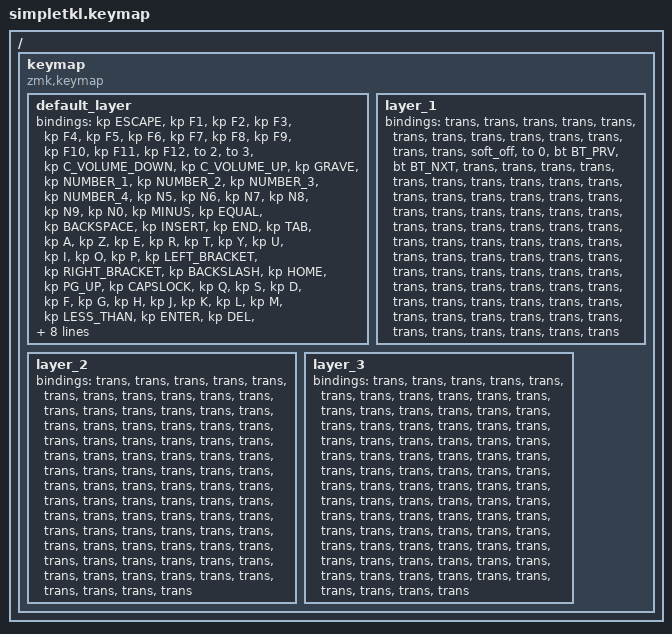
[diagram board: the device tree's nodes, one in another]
/*
 * Keymap for: simpletkl
 *
 * This keymap MUST match your PHYSICAL layout (17 rows, 6 columns).
 * Use &none for any empty spots in the matrix.
 */

#include <dt-bindings/zmk/matrix_transform.h> // Required for matrix_transform
#include <behaviors.dtsi>
#include <dt-bindings/zmk/bt.h>
#include <dt-bindings/zmk/keys.h>

/ {
    keymap {
        compatible = "zmk,keymap";

        default_layer {
            bindings = <
&kp ESCAPE  &kp F1  &kp F2  &kp F3  &kp F4  &kp F5  &kp F6  &kp F7  &kp F8  &kp F9  &kp F10  &kp F11  &kp F12  &to 2  &to 3  &kp C_VOLUME_DOWN  &kp C_VOLUME_UP  &kp GRAVE  &kp NUMBER_1  &kp NUMBER_2  &kp NUMBER_3  &kp NUMBER_4  &kp N5  &kp N6  &kp N7  &kp N8  &kp N9  &kp N0  &kp MINUS  &kp EQUAL  &kp BACKSPACE  &kp INSERT  &kp END  &kp TAB  &kp A  &kp Z  &kp E  &kp R  &kp T  &kp Y  &kp U  &kp I  &kp O  &kp P  &kp LEFT_BRACKET  &kp RIGHT_BRACKET  &kp BACKSLASH  &kp HOME  &kp PG_UP  &kp CAPSLOCK  &kp Q  &kp S  &kp D  &kp F  &kp G  &kp H  &kp J  &kp K  &kp L  &kp M  &kp LESS_THAN  &kp ENTER  &kp DEL  &kp PAGE_DOWN  &kp LEFT_SHIFT  &kp W  &kp X  &kp C  &kp V  &kp B  &kp N  &kp COMMA  &kp SEMICOLON  &kp SLASH  &kp GREATER_THAN  &kp RIGHT_SHIFT  &kp UP_ARROW  &kp LEFT_CONTROL  &kp LEFT_WIN  &kp LEFT_ALT  &kp SPACE  &kp LEFT_ALT  &mo 1  &kp RIGHT_CONTROL  &kp LEFT_ARROW  &kp DOWN_ARROW  &kp RIGHT_ARROW
            >;
        };

        layer_1 {
            bindings = <
&trans  &trans  &trans  &trans  &trans  &trans  &trans  &trans  &trans  &trans  &trans  &trans  &trans  &soft_off  &to 0  &bt BT_PRV  &bt BT_NXT  &trans  &trans  &trans  &trans  &trans  &trans  &trans  &trans  &trans  &trans  &trans  &trans  &trans  &trans  &trans  &trans  &trans  &trans  &trans  &trans  &trans  &trans  &trans  &trans  &trans  &trans  &trans  &trans  &trans  &trans  &trans  &trans  &trans  &trans  &trans  &trans  &trans  &trans  &trans  &trans  &trans  &trans  &trans  &trans  &trans  &trans  &trans  &trans  &trans  &trans  &trans  &trans  &trans  &trans  &trans  &trans  &trans  &trans  &trans  &trans  &trans  &trans  &trans  &trans  &trans  &trans  &trans  &trans  &trans  &trans
            >;
        };

        layer_2 {
            bindings = <
&trans  &trans  &trans  &trans  &trans  &trans  &trans  &trans  &trans  &trans  &trans  &trans  &trans  &trans  &trans  &trans  &trans  &trans  &trans  &trans  &trans  &trans  &trans  &trans  &trans  &trans  &trans  &trans  &trans  &trans  &trans  &trans  &trans  &trans  &trans  &trans  &trans  &trans  &trans  &trans  &trans  &trans  &trans  &trans  &trans  &trans  &trans  &trans  &trans  &trans  &trans  &trans  &trans  &trans  &trans  &trans  &trans  &trans  &trans  &trans  &trans  &trans  &trans  &trans  &trans  &trans  &trans  &trans  &trans  &trans  &trans  &trans  &trans  &trans  &trans  &trans  &trans  &trans  &trans  &trans  &trans  &trans  &trans  &trans  &trans  &trans  &trans
            >;
        };

        layer_3 {
            bindings = <
&trans  &trans  &trans  &trans  &trans  &trans  &trans  &trans  &trans  &trans  &trans  &trans  &trans  &trans  &trans  &trans  &trans  &trans  &trans  &trans  &trans  &trans  &trans  &trans  &trans  &trans  &trans  &trans  &trans  &trans  &trans  &trans  &trans  &trans  &trans  &trans  &trans  &trans  &trans  &trans  &trans  &trans  &trans  &trans  &trans  &trans  &trans  &trans  &trans  &trans  &trans  &trans  &trans  &trans  &trans  &trans  &trans  &trans  &trans  &trans  &trans  &trans  &trans  &trans  &trans  &trans  &trans  &trans  &trans  &trans  &trans  &trans  &trans  &trans  &trans  &trans  &trans  &trans  &trans  &trans  &trans  &trans  &trans  &trans  &trans  &trans  &trans
            >;
        };
    };
};
